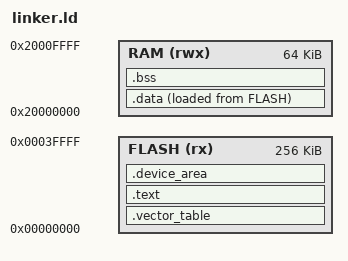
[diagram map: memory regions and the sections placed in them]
/* lm3s6965evb: 256KB flash at 0x00000000, 64KB RAM at 0x20000000 */
MEMORY
{
    FLASH (rx)  : ORIGIN = 0x00000000, LENGTH = 256K
    RAM   (rwx) : ORIGIN = 0x20000000, LENGTH = 64K
}

ENTRY(reset_handler)

SECTIONS
{
    .vector_table :
    {
        KEEP(*(.vector_table))
    } > FLASH

    .text :
    {
        *(.text)
        *(.text.*)
        *(.rodata)
        *(.rodata.*)
    } > FLASH

    .device_area :
    {
        _device_start = .;
        KEEP(*(device_area))
        _device_end = .;
    } > FLASH

    _data_flash = LOADADDR(.data);
    .data :
    {
        _data_start = .;
        *(.data)
        *(.data.*)
        _data_end = .;
    } > RAM AT > FLASH

    .bss :
    {
        _bss_start = .;
        *(.bss)
        *(.bss.*)
        *(COMMON)
        _bss_end = .;
    } > RAM

    _stack_top = ORIGIN(RAM) + LENGTH(RAM);
}
